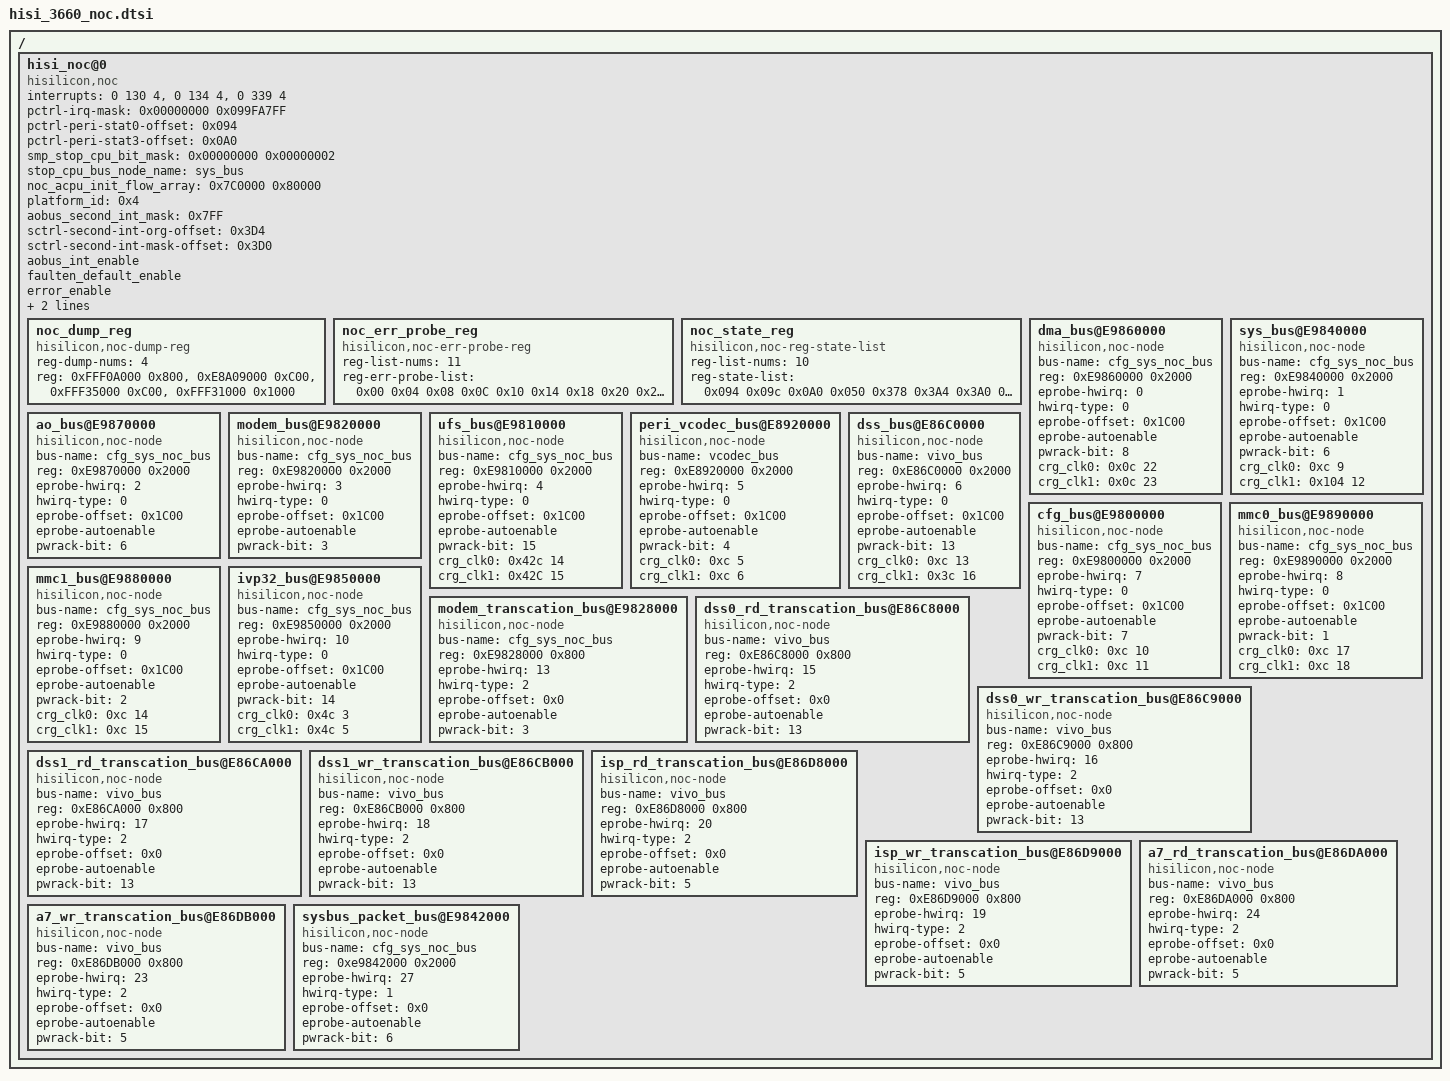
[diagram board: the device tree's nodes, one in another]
/{
	hisi_noc@0 {
		#address-cells = <1>;
		#size-cells = <1>;
		ranges;
		compatible = "hisilicon,noc";
		interrupts = <0 130 4>,<0 134 4>,<0 339 4>;
		pctrl-irq-mask = <0x00000000 0x099FA7FF>;
		pctrl-peri-stat0-offset = <0x094>;
		pctrl-peri-stat3-offset = <0x0A0>;
		smp_stop_cpu_bit_mask = <0x00000000 0x00000002>;  /* 0x8: 0000 0010B, Sys Bus NoC Error need stop cpu immediately.*/
		stop_cpu_bus_node_name = "sys_bus";
		noc_acpu_init_flow_array = <0x7C0000 0x80000>; /*Mask, Value*/		
		platform_id = <0x4>;/* hisi3660(chicago) platform */
		aobus_second_int_mask = <0x7FF>;
		sctrl-second-int-org-offset = <0x3D4>;
		sctrl-second-int-mask-offset = <0x3D0>;
		aobus_int_enable;
		faulten_default_enable;
		error_enable;
		noc_timeout_enable;
		/*fama_enable;*/
		fama-mask = <0x1F>;

		noc_dump_reg {
			compatible = "hisilicon,noc-dump-reg";
			reg-dump-nums = <4>;
			reg = <0xFFF0A000 0x800>,/*sctrl_base_addr*/
			      <0xE8A09000 0xC00>,/*pctrl_base_addr*/
			      <0xFFF35000 0xC00>,/*peri_crg_base_addr*/
			      <0xFFF31000 0x1000>;/*pmctrl_base_addr*/
		};

		noc_err_probe_reg {
			compatible = "hisilicon,noc-err-probe-reg";
			reg-list-nums = <11>;
			/*reg-list-offset: coreid, revisionid, faulten, errvld, errclr, errlog0, errlog1, errlog3, errlog4, errlog5, errlog7 */
			reg-err-probe-list = <0x00 0x04 0x08 0x0C 0x10 0x14 0x18 0x20 0x24 0x28 0x30>;
		};

		noc_state_reg {
			compatible = "hisilicon,noc-reg-state-list";
			reg-list-nums = <10>;
			/*reg-list-offset: pctrl_stat0, pctrl_stat2, pctrl_stat3, pctrl_ctrl19, sctrl_scperstatus6, pmctrl_int0_stat, pmctrl_int0_mask, pmctrl_power_idlereq, pmctrl_power_idleack, pmctrl_power_idle*/
			reg-state-list = <0x094 0x09c 0x0A0 0x050 0x378 0x3A4 0x3A0 0x380 0x384 0x388>;
		};

        dma_bus@E9860000 {
			compatible = "hisilicon,noc-node";
			bus-name = "cfg_sys_noc_bus";
			reg = <0xE9860000 0x2000>;
			eprobe-hwirq = <0>;
			hwirq-type = <0>;
			eprobe-offset = <0x1C00>;
			eprobe-autoenable;
			pwrack-bit = <8>;
			crg_clk0=<0x0c 22>;
			crg_clk1=<0x0c 23>;
		};

		sys_bus@E9840000 {
			compatible = "hisilicon,noc-node";
			bus-name = "cfg_sys_noc_bus";
			reg = <0xE9840000 0x2000>;
			eprobe-hwirq = <1>;
			hwirq-type = <0>;
			eprobe-offset = <0x1C00>;
			eprobe-autoenable;
			pwrack-bit = <6>;
			crg_clk0=<0xc 9>;
			crg_clk1=<0x104 12>;
		};

        ao_bus@E9870000 {
			compatible = "hisilicon,noc-node";
			bus-name = "cfg_sys_noc_bus";
			reg = <0xE9870000 0x2000>;
			eprobe-hwirq = <2>;
			hwirq-type = <0>;
			eprobe-offset = <0x1C00>;
			eprobe-autoenable;
			/*AO bus is always on and no bit controls it,
			  we use a fake control bit which keeps 1 as sysbus*/
			pwrack-bit = <6>;
		};

		modem_bus@E9820000 {
			compatible = "hisilicon,noc-node";
			bus-name = "cfg_sys_noc_bus";
			reg = <0xE9820000 0x2000>;
			eprobe-hwirq = <3>;
			hwirq-type = <0>;
			eprobe-offset = <0x1C00>;
			eprobe-autoenable;
			pwrack-bit = <3>;
		};

        ufs_bus@E9810000 {
			compatible = "hisilicon,noc-node";
			bus-name = "cfg_sys_noc_bus";
			reg = <0xE9810000 0x2000>;
			eprobe-hwirq = <4>;
			hwirq-type = <0>;
			eprobe-offset = <0x1C00>;
			eprobe-autoenable;
			pwrack-bit = <15>;
			crg_clk0=<0x42c 14>;
			crg_clk1=<0x42C 15>;
		};

		peri_vcodec_bus@E8920000 {
			compatible = "hisilicon,noc-node";
			bus-name = "vcodec_bus";
			reg = <0xE8920000 0x2000>;
			eprobe-hwirq = <5>;
			hwirq-type = <0>;
			eprobe-offset = <0x1C00>;
			eprobe-autoenable;
			pwrack-bit = <4>;
			crg_clk0=<0xc 5>;
			crg_clk1=<0xc 6>;
		};

		dss_bus@E86C0000 {
			compatible = "hisilicon,noc-node";
			bus-name = "vivo_bus";
			reg = <0xE86C0000 0x2000>;
			eprobe-hwirq = <6>;
			hwirq-type = <0>;
			eprobe-offset = <0x1C00>;
			eprobe-autoenable;
			pwrack-bit = <13>;
			crg_clk0=<0xc 13>;
			crg_clk1=<0x3c 16>;
		};

		cfg_bus@E9800000 {
			compatible = "hisilicon,noc-node";
			bus-name = "cfg_sys_noc_bus";
			reg = <0xE9800000 0x2000>;
			eprobe-hwirq = <7>;
			hwirq-type = <0>;
			eprobe-offset = <0x1C00>;
			eprobe-autoenable;
			pwrack-bit = <7>;
			crg_clk0=<0xc 10>;
			crg_clk1=<0xc 11>;
		};

		mmc0_bus@E9890000 {
			compatible = "hisilicon,noc-node";
			bus-name = "cfg_sys_noc_bus";
			reg = <0xE9890000 0x2000>;
			eprobe-hwirq = <8>;
			hwirq-type = <0>;
			eprobe-offset = <0x1C00>;
			eprobe-autoenable;
			pwrack-bit = <1>;
			crg_clk0=<0xc 17>;
			crg_clk1=<0xc 18>;
		};

		mmc1_bus@E9880000 {
			compatible = "hisilicon,noc-node";
			bus-name = "cfg_sys_noc_bus";
			reg = <0xE9880000 0x2000>;
			eprobe-hwirq = <9>;
			hwirq-type = <0>;
			eprobe-offset = <0x1C00>;
			eprobe-autoenable;
			pwrack-bit = <2>;
			crg_clk0=<0xc 14>;
			crg_clk1=<0xc 15>;
		};

		ivp32_bus@E9850000 {
			compatible = "hisilicon,noc-node";
			bus-name = "cfg_sys_noc_bus";
			reg = <0xE9850000 0x2000>;
			eprobe-hwirq = <10>;
			hwirq-type = <0>;
			eprobe-offset = <0x1C00>;
			eprobe-autoenable;
			pwrack-bit = <14>;
			crg_clk0=<0x4c 3>;
			crg_clk1=<0x4c 5>;
		};

		modem_transcation_bus@E9828000 {
			compatible = "hisilicon,noc-node";
			bus-name = "cfg_sys_noc_bus";
			reg = <0xE9828000 0x800>;
			eprobe-hwirq = <13>;
			hwirq-type = <2>;
			eprobe-offset = <0x0>;
			eprobe-autoenable;
			pwrack-bit = <3>;
		};

        dss0_rd_transcation_bus@E86C8000 {
			compatible = "hisilicon,noc-node";
			bus-name = "vivo_bus";
			reg = <0xE86C8000 0x800>;
			eprobe-hwirq = <15>;
			hwirq-type = <2>;
			eprobe-offset = <0x0>;
			eprobe-autoenable;
			pwrack-bit = <13>;
		};

		dss0_wr_transcation_bus@E86C9000 {
			compatible = "hisilicon,noc-node";
			bus-name = "vivo_bus";
			reg = <0xE86C9000 0x800>;
			eprobe-hwirq = <16>;
			hwirq-type = <2>;
			eprobe-offset = <0x0>;
			eprobe-autoenable;
			pwrack-bit = <13>; 
		};

		dss1_rd_transcation_bus@E86CA000 {
			compatible = "hisilicon,noc-node";
			bus-name = "vivo_bus";
			reg = <0xE86CA000 0x800>;
			eprobe-hwirq = <17>;
			hwirq-type = <2>;
			eprobe-offset = <0x0>;
			eprobe-autoenable;
			pwrack-bit = <13>;
		};

		dss1_wr_transcation_bus@E86CB000 {
			compatible = "hisilicon,noc-node";
			bus-name = "vivo_bus";
			reg = <0xE86CB000 0x800>;
			eprobe-hwirq = <18>;
			hwirq-type = <2>;
			eprobe-offset = <0x0>;
			eprobe-autoenable;
			pwrack-bit = <13>;
		};

		isp_rd_transcation_bus@E86D8000 {
			compatible = "hisilicon,noc-node";
			bus-name = "vivo_bus";
			reg = <0xE86D8000 0x800>;
			eprobe-hwirq = <20>;
			hwirq-type = <2>;
			eprobe-offset = <0x0>;
			eprobe-autoenable;
			pwrack-bit = <5>; 
		};

		isp_wr_transcation_bus@E86D9000 {
			compatible = "hisilicon,noc-node";
			bus-name = "vivo_bus";
			reg = <0xE86D9000 0x800>;
			eprobe-hwirq = <19>;
			hwirq-type = <2>;
			eprobe-offset = <0x0>;
			eprobe-autoenable;
			pwrack-bit = <5>; 
		};

		a7_rd_transcation_bus@E86DA000 {
			compatible = "hisilicon,noc-node";
			bus-name = "vivo_bus";
			reg = <0xE86DA000 0x800>;
			eprobe-hwirq = <24>;
			hwirq-type = <2>;
			eprobe-offset = <0x0>;
			eprobe-autoenable;
			pwrack-bit = <5>; 
		};

		a7_wr_transcation_bus@E86DB000 {
			compatible = "hisilicon,noc-node";
			bus-name = "vivo_bus";
			reg = <0xE86DB000 0x800>;
			eprobe-hwirq = <23>;
			hwirq-type = <2>;
			eprobe-offset = <0x0>;
			eprobe-autoenable;
			pwrack-bit = <5>; 
		};

		sysbus_packet_bus@E9842000 {
			compatible = "hisilicon,noc-node";
			bus-name = "cfg_sys_noc_bus";
			reg = <0xe9842000 0x2000>;
			eprobe-hwirq = <27>;
			hwirq-type = <1>;
			eprobe-offset = <0x0>;
			eprobe-autoenable;
			pwrack-bit = <6>;
		};
	}; /* end of hisi_noc */
};
